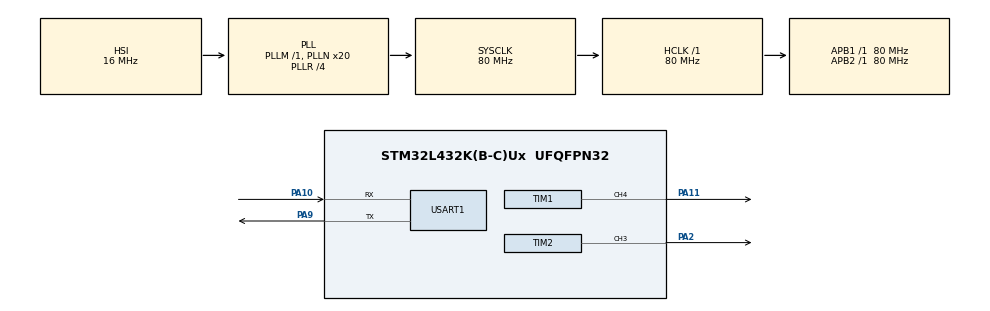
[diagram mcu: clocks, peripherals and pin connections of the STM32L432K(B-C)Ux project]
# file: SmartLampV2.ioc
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Dma.Request0=TIM2_CH3
Dma.TIM2_CH3.0.Direction=DMA_MEMORY_TO_PERIPH
Dma.TIM2_CH3.0.Instance=DMA1_Channel1
Dma.TIM2_CH3.0.MemDataAlignment=DMA_MDATAALIGN_HALFWORD
Dma.TIM2_CH3.0.MemInc=DMA_MINC_ENABLE
Dma.TIM2_CH3.0.Mode=DMA_NORMAL
Dma.TIM2_CH3.0.PeriphDataAlignment=DMA_PDATAALIGN_HALFWORD
Dma.TIM2_CH3.0.PeriphInc=DMA_PINC_DISABLE
Dma.TIM2_CH3.0.Priority=DMA_PRIORITY_HIGH
Mcu.Family=STM32L4
Mcu.Name=STM32L432K(B-C)Ux
Mcu.Package=UFQFPN32
NVIC.DMA1_Channel1_IRQn=true\:0\:0\:false\:false\:true\:false\:true
NVIC.PriorityGroup=NVIC_PRIORITYGROUP_4
PA0.GPIO_Label=MCO [High speed clock in]
PA0.Mode=HSE-External-Clock-Source-for-LittleOrca
PA0.Signal=RCC_CK_IN
PA10.Mode=Asynchronous
PA10.Signal=USART1_RX
PA11.Signal=S_TIM1_CH4
PA13\ (JTMS-SWDIO).GPIO_Label=SWDIO
PA13\ (JTMS-SWDIO).Mode=Serial_Wire
PA13\ (JTMS-SWDIO).Signal=SYS_JTMS-SWDIO
PA14\ (JTCK-SWCLK).GPIO_Label=SWCLK
PA14\ (JTCK-SWCLK).Mode=Serial_Wire
PA14\ (JTCK-SWCLK).Signal=SYS_JTCK-SWCLK
PA15\ (JTDI).GPIO_Label=VCP_RX
PA15\ (JTDI).Signal=USART2_RX
PA2.Signal=S_TIM2_CH3
PA9.Mode=Asynchronous
PA9.Signal=USART1_TX
PC14-OSC32_IN\ (PC14).Mode=LSE-External-Oscillator
PC14-OSC32_IN\ (PC14).Signal=RCC_OSC32_IN
PC15-OSC32_OUT\ (PC15).Mode=LSE-External-Oscillator
PC15-OSC32_OUT\ (PC15).Signal=RCC_OSC32_OUT
ProjectManager.HeapSize=0x200
ProjectManager.StackSize=0x400
ProjectManager.TargetToolchain=SW4STM32
RCC.ADCFreq_Value=64000000
RCC.AHBFreq_Value=80000000
RCC.APB1Freq_Value=80000000
RCC.APB1TimFreq_Value=80000000
RCC.APB2Freq_Value=80000000
RCC.APB2TimFreq_Value=80000000
RCC.CortexFreq_Value=80000000
RCC.HCLKFreq_Value=80000000
RCC.HSE_VALUE=8000000
RCC.HSI16_VALUE=16000000
RCC.HSI48_VALUE=48000000
RCC.HSI_VALUE=16000000
RCC.MSI_VALUE=4000000
RCC.PLLMUL=RCC_PLLMUL_4
RCC.PLLN=20
RCC.PLLR=RCC_PLLR_DIV4
RCC.PLLSourceVirtual=RCC_PLLSOURCE_HSI
RCC.SYSCLKFreq_VALUE=80000000
RCC.SYSCLKSource=RCC_SYSCLKSOURCE_PLLCLK
RCC.USBFreq_Value=64000000
RCC.VCOOutputFreq_Value=320000000
SH.S_TIM1_CH4.0=TIM1_CH4,Output Compare4 CH4
SH.S_TIM2_CH3.0=TIM2_CH3,PWM Generation3 CH3
TIM1.Channel-Output\ Compare4\ CH4=TIM_CHANNEL_4
TIM1.OC4Preload=DISABLE
TIM1.OCMode_4=TIM_OCMODE_TOGGLE
TIM1.Period=1221
TIM1.Prescaler=65535
TIM1.Pulse-Output\ Compare4\ CH4=250
TIM2.AutoReloadPreload=TIM_AUTORELOAD_PRELOAD_DISABLE
TIM2.Channel-PWM\ Generation3\ CH3=TIM_CHANNEL_3
TIM2.Period=100-1
TIM2.Prescaler=0
USART1.VirtualMode-Asynchronous=VM_ASYNC
VP_TIM2_VS_ClockSourceINT.Mode=Internal
board=NUCLEO-L432KC

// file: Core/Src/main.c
/* USER CODE BEGIN Header */
/**
  ******************************************************************************
  * @file           : main.c
  * @brief          : Main program body
  ******************************************************************************
  * @attention
  *
  * <h2><center>&copy; Copyright (c) 2021 STMicroelectronics.
  * All rights reserved.</center></h2>
  *
  * This software component is licensed by ST under BSD 3-Clause license,
  * the "License"; You may not use this file except in compliance with the
  * License. You may obtain a copy of the License at:
  *                        opensource.org/licenses/BSD-3-Clause
  *
  ******************************************************************************
  */
/* USER CODE END Header */
#include "main.h"
#include <math.h>
#include "ws2812b.h"
#include "visEffect.h"

#define MAX_LED 8
#define USE_BRIGHTNESS 1
#define PI 3.14159265

// DEBUG OUTPUT
// ********************
#define LED4_PORT GPIOA
#define LED4_PIN GPIO_PIN_4

#define LED5_PORT GPIOA
#define LED5_PIN GPIO_PIN_5

TIM_HandleTypeDef htim1;
TIM_HandleTypeDef htim2;
DMA_HandleTypeDef hdma_tim2_ch3;
UART_HandleTypeDef huart1;

void SystemClock_Config(void);
static void MX_GPIO_Init(void);
static void MX_DMA_Init(void);
static void MX_TIM2_Init(void);
static void MX_TIM1_Init(void);
static void MX_USART1_UART_Init(void);

int datasentflag=0;
uint32_t timer_period;
uint8_t compare_pulse_logic_0;
uint8_t compare_pulse_logic_1;

int main(void)
{
  HAL_Init();
  SystemClock_Config();

  MX_GPIO_Init();
  MX_DMA_Init();
  MX_TIM2_Init();
  MX_TIM1_Init();
  MX_USART1_UART_Init();

  visInit();

  while (1)
  {
	  visHandle();
  }
}

void SystemClock_Config(void)
{
  RCC_OscInitTypeDef RCC_OscInitStruct = {0};
  RCC_ClkInitTypeDef RCC_ClkInitStruct = {0};
  RCC_PeriphCLKInitTypeDef PeriphClkInit = {0};

  /** Initializes the RCC Oscillators according to the specified parameters
  * in the RCC_OscInitTypeDef structure.
  */
  RCC_OscInitStruct.OscillatorType = RCC_OSCILLATORTYPE_HSI;
  RCC_OscInitStruct.HSIState = RCC_HSI_ON;
  RCC_OscInitStruct.HSICalibrationValue = RCC_HSICALIBRATION_DEFAULT;
  RCC_OscInitStruct.PLL.PLLState = RCC_PLL_ON;
  RCC_OscInitStruct.PLL.PLLSource = RCC_PLLSOURCE_HSI;
  RCC_OscInitStruct.PLL.PLLM = 1;
  RCC_OscInitStruct.PLL.PLLN = 20;
  RCC_OscInitStruct.PLL.PLLP = RCC_PLLP_DIV7;
  RCC_OscInitStruct.PLL.PLLQ = RCC_PLLQ_DIV2;
  RCC_OscInitStruct.PLL.PLLR = RCC_PLLR_DIV4;
  if (HAL_RCC_OscConfig(&RCC_OscInitStruct) != HAL_OK)
  {
    Error_Handler();
  }
  /** Initializes the CPU, AHB and APB buses clocks
  */
  RCC_ClkInitStruct.ClockType = RCC_CLOCKTYPE_HCLK|RCC_CLOCKTYPE_SYSCLK
                              |RCC_CLOCKTYPE_PCLK1|RCC_CLOCKTYPE_PCLK2;
  RCC_ClkInitStruct.SYSCLKSource = RCC_SYSCLKSOURCE_PLLCLK;
  RCC_ClkInitStruct.AHBCLKDivider = RCC_SYSCLK_DIV1;
  RCC_ClkInitStruct.APB1CLKDivider = RCC_HCLK_DIV1;
  RCC_ClkInitStruct.APB2CLKDivider = RCC_HCLK_DIV1;

  if (HAL_RCC_ClockConfig(&RCC_ClkInitStruct, FLASH_LATENCY_4) != HAL_OK)
  {
    Error_Handler();
  }
  PeriphClkInit.PeriphClockSelection = RCC_PERIPHCLK_USART1;
  PeriphClkInit.Usart1ClockSelection = RCC_USART1CLKSOURCE_PCLK2;
  if (HAL_RCCEx_PeriphCLKConfig(&PeriphClkInit) != HAL_OK)
  {
    Error_Handler();
  }
  /** Configure the main internal regulator output voltage
  */
  if (HAL_PWREx_ControlVoltageScaling(PWR_REGULATOR_VOLTAGE_SCALE1) != HAL_OK)
  {
    Error_Handler();
  }
}

static void MX_TIM1_Init(void)
{

  TIM_MasterConfigTypeDef sMasterConfig = {0};
  TIM_OC_InitTypeDef sConfigOC = {0};
  TIM_BreakDeadTimeConfigTypeDef sBreakDeadTimeConfig = {0};

  htim1.Instance = TIM1;
  htim1.Init.Prescaler = 65535;
  htim1.Init.CounterMode = TIM_COUNTERMODE_UP;
  htim1.Init.Period = 1221;
  htim1.Init.ClockDivision = TIM_CLOCKDIVISION_DIV1;
  htim1.Init.RepetitionCounter = 0;
  htim1.Init.AutoReloadPreload = TIM_AUTORELOAD_PRELOAD_DISABLE;
  if (HAL_TIM_OC_Init(&htim1) != HAL_OK)
  {
    Error_Handler();
  }
  sMasterConfig.MasterOutputTrigger = TIM_TRGO_RESET;
  sMasterConfig.MasterOutputTrigger2 = TIM_TRGO2_RESET;
  sMasterConfig.MasterSlaveMode = TIM_MASTERSLAVEMODE_DISABLE;
  if (HAL_TIMEx_MasterConfigSynchronization(&htim1, &sMasterConfig) != HAL_OK)
  {
    Error_Handler();
  }
  sConfigOC.OCMode = TIM_OCMODE_TOGGLE;
  sConfigOC.Pulse = 250;
  sConfigOC.OCPolarity = TIM_OCPOLARITY_HIGH;
  sConfigOC.OCFastMode = TIM_OCFAST_DISABLE;
  sConfigOC.OCIdleState = TIM_OCIDLESTATE_RESET;
  sConfigOC.OCNIdleState = TIM_OCNIDLESTATE_RESET;
  if (HAL_TIM_OC_ConfigChannel(&htim1, &sConfigOC, TIM_CHANNEL_4) != HAL_OK)
  {
    Error_Handler();
  }
  sBreakDeadTimeConfig.OffStateRunMode = TIM_OSSR_DISABLE;
  sBreakDeadTimeConfig.OffStateIDLEMode = TIM_OSSI_DISABLE;
  sBreakDeadTimeConfig.LockLevel = TIM_LOCKLEVEL_OFF;
  sBreakDeadTimeConfig.DeadTime = 0;
  sBreakDeadTimeConfig.BreakState = TIM_BREAK_DISABLE;
  sBreakDeadTimeConfig.BreakPolarity = TIM_BREAKPOLARITY_HIGH;
  sBreakDeadTimeConfig.BreakFilter = 0;
  sBreakDeadTimeConfig.Break2State = TIM_BREAK2_DISABLE;
  sBreakDeadTimeConfig.Break2Polarity = TIM_BREAK2POLARITY_HIGH;
  sBreakDeadTimeConfig.Break2Filter = 0;
  sBreakDeadTimeConfig.AutomaticOutput = TIM_AUTOMATICOUTPUT_DISABLE;
  if (HAL_TIMEx_ConfigBreakDeadTime(&htim1, &sBreakDeadTimeConfig) != HAL_OK)
  {
    Error_Handler();
  }
  HAL_TIM_MspPostInit(&htim1);
  HAL_TIM_OC_Start(&htim1, TIM_CHANNEL_4);
}

static void MX_TIM2_Init(void)
{

  TIM_ClockConfigTypeDef sClockSourceConfig = {0};
  TIM_MasterConfigTypeDef sMasterConfig = {0};
  TIM_OC_InitTypeDef sConfigOC = {0};

  htim2.Instance = TIM2;
  htim2.Init.Prescaler = 0;
  htim2.Init.CounterMode = TIM_COUNTERMODE_UP;
  htim2.Init.Period = 115; // this value should be 100 but apparently 115
  htim2.Init.ClockDivision = TIM_CLOCKDIVISION_DIV1;
  htim2.Init.AutoReloadPreload = TIM_AUTORELOAD_PRELOAD_DISABLE;
  if (HAL_TIM_Base_Init(&htim2) != HAL_OK)
  {
    Error_Handler();
  }
  sClockSourceConfig.ClockSource = TIM_CLOCKSOURCE_INTERNAL;
  if (HAL_TIM_ConfigClockSource(&htim2, &sClockSourceConfig) != HAL_OK)
  {
    Error_Handler();
  }
  if (HAL_TIM_PWM_Init(&htim2) != HAL_OK)
  {
    Error_Handler();
  }
  sMasterConfig.MasterOutputTrigger = TIM_TRGO_RESET;
  sMasterConfig.MasterSlaveMode = TIM_MASTERSLAVEMODE_DISABLE;
  if (HAL_TIMEx_MasterConfigSynchronization(&htim2, &sMasterConfig) != HAL_OK)
  {
    Error_Handler();
  }
  /*
   * hubmartin timer pulse logic
   * This logic calculates the timer period from the system clock. The result will be two values to be used in the
   * pulse changing logic
   */
	timer_period =  (SystemCoreClock / 800000) + 15; // 0,125us period (10 times lower the 1,25us period to have fixed math below)

	uint32_t logic_0 = (10 * timer_period) / 26; // originally 36
	uint32_t logic_1 = (10 * timer_period) / 6; // originally 15

	if(logic_0 > 255 || logic_1 > 255)
	{
		// Error, compare_pulse_logic_0 or compare_pulse_logic_1 needs to be redefined to uint16_t (but it takes more memory)
		for(;;);
	}
	compare_pulse_logic_0 = logic_0;
	compare_pulse_logic_1 = logic_1;

	// TODO: need to check the DCR register in debug

  sConfigOC.OCMode = TIM_OCMODE_PWM1;
  sConfigOC.Pulse = compare_pulse_logic_0; // previously 0 via cubemx config
  sConfigOC.OCPolarity = TIM_OCPOLARITY_HIGH;
  sConfigOC.OCFastMode = TIM_OCFAST_DISABLE;
  if (HAL_TIM_PWM_ConfigChannel(&htim2, &sConfigOC, TIM_CHANNEL_3) != HAL_OK)
  {
    Error_Handler();
  }
  /* USER CODE BEGIN TIM2_Init 2 */

	(&htim2)->Instance->DCR = TIM_DMABASE_CCR3 | TIM_DMABURSTLENGTH_1TRANSFER;
	// enable DMA interrupts for TIM2
	(&htim2)->Instance->DIER |= (1 << 3) | (1 << 11); // 3 = CC3IE, 11 = CC3DE

  // configure registers before starting the PWM?
	HAL_TIM_PWM_Start(&htim2, TIM_CHANNEL_3);
	  // needed for period elapsed callback
	  if (HAL_TIM_Base_Start_IT(&htim2) != HAL_OK)
	  {
	    Error_Handler();
	  }

	// if there is a ccr match, the CCxIF register needs to be cleared by software

  /* USER CODE END TIM2_Init 2 */
  HAL_TIM_MspPostInit(&htim2);
}

static void MX_USART1_UART_Init(void)
{

  huart1.Instance = USART1;
  huart1.Init.BaudRate = 115200;
  huart1.Init.WordLength = UART_WORDLENGTH_8B;
  huart1.Init.StopBits = UART_STOPBITS_1;
  huart1.Init.Parity = UART_PARITY_NONE;
  huart1.Init.Mode = UART_MODE_TX_RX;
  huart1.Init.HwFlowCtl = UART_HWCONTROL_NONE;
  huart1.Init.OverSampling = UART_OVERSAMPLING_16;
  huart1.Init.OneBitSampling = UART_ONE_BIT_SAMPLE_DISABLE;
  huart1.AdvancedInit.AdvFeatureInit = UART_ADVFEATURE_NO_INIT;
  if (HAL_UART_Init(&huart1) != HAL_OK)
  {
    Error_Handler();
  }

}

static void MX_DMA_Init(void)
{

  /* DMA controller clock enable */
  __HAL_RCC_DMA1_CLK_ENABLE();

  /* DMA interrupt init */
  /* DMA1_Channel1_IRQn interrupt configuration */
  HAL_NVIC_SetPriority(DMA1_Channel1_IRQn, 0, 0);
  HAL_NVIC_EnableIRQ(DMA1_Channel1_IRQn);

//  HAL_DMA_Start_IT(&hdma_tim2_ch3, (uint32_t)pwmData, (uint32_t)&TIM2->CCR1, BUFFER_SIZE);

}

static void MX_GPIO_Init(void)
{
  GPIO_InitTypeDef GPIO_InitStruct = {0};

  /* GPIO Ports Clock Enable */
  __HAL_RCC_GPIOC_CLK_ENABLE();
  __HAL_RCC_GPIOA_CLK_ENABLE();

  /*Configure GPIO pin : VCP_RX_Pin */
  GPIO_InitStruct.Pin = VCP_RX_Pin;
  GPIO_InitStruct.Mode = GPIO_MODE_AF_PP;
  GPIO_InitStruct.Pull = GPIO_NOPULL;
  GPIO_InitStruct.Speed = GPIO_SPEED_FREQ_VERY_HIGH;
  GPIO_InitStruct.Alternate = GPIO_AF3_USART2;
  HAL_GPIO_Init(VCP_RX_GPIO_Port, &GPIO_InitStruct);

	// Enable output pins for debuging to see DMA Full and Half transfer interrupts
#if defined(LED4_PORT) && defined(LED5_PORT)
	GPIO_InitStruct.Mode = GPIO_MODE_OUTPUT_PP;
	GPIO_InitStruct.Pull = GPIO_NOPULL;
	GPIO_InitStruct.Speed = GPIO_SPEED_FREQ_HIGH;

	GPIO_InitStruct.Pin = LED4_PIN;
	HAL_GPIO_Init(LED4_PORT, &GPIO_InitStruct);
	GPIO_InitStruct.Pin = LED5_PIN;
	HAL_GPIO_Init(LED5_PORT, &GPIO_InitStruct);
#endif
}

void Error_Handler(void)
{
  __disable_irq();
  while (1)
  {
  }
}

/************************ (C) COPYRIGHT STMicroelectronics *****END OF FILE****/
